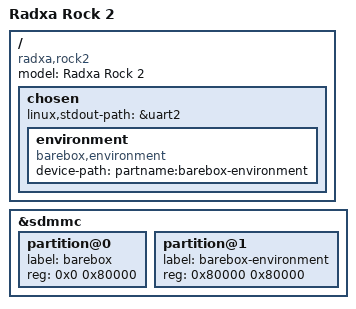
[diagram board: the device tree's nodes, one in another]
/*
 * Copyright (c) 2013 Heiko Stuebner <heiko@sntech.de>
 *
 * This program is free software; you can redistribute it and/or modify
 * it under the terms of the GNU General Public License as published by
 * the Free Software Foundation; either version 2 of the License, or
 * (at your option) any later version.
 *
 * This program is distributed in the hope that it will be useful,
 * but WITHOUT ANY WARRANTY; without even the implied warranty of
 * MERCHANTABILITY or FITNESS FOR A PARTICULAR PURPOSE.  See the
 * GNU General Public License for more details.
 */

#include <arm/rk3288-firefly.dts>

/ {
	model = "Radxa Rock 2";
	compatible = "radxa,rock2", "firefly,firefly-rk3288", "rockchip,rk3288";

	chosen {
		linux,stdout-path = &uart2;

		environment {
			compatible = "barebox,environment";
			device-path = &sdmmc, "partname:barebox-environment";
			status = "okay";
		};
	};
};

&sdmmc {
	#address-cells = <1>;
	#size-cells = <1>;

	partition@0 {
		label = "barebox";
		reg = <0x0 0x80000>;
	};
	partition@1 {
		label = "barebox-environment";
		reg = <0x80000 0x80000>;
	};
};
